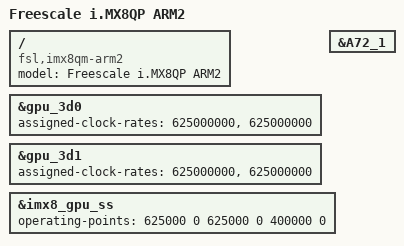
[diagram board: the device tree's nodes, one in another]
/*
 * Copyright (C) 2016 Freescale Semiconductor, Inc.
 * Copyright 2018 NXP
 *
 * This program is free software; you can redistribute it and/or
 * modify it under the terms of the GNU General Public License
 * as published by the Free Software Foundation; either version 2
 * of the License, or (at your option) any later version.
 *
 * This program is distributed in the hope that it will be useful,
 * but WITHOUT ANY WARRANTY; without even the implied warranty of
 * MERCHANTABILITY or FITNESS FOR A PARTICULAR PURPOSE.  See the
 * GNU General Public License for more details.
 */

#include "fsl-imx8qm-lpddr4-arm2.dts"

/ {
        model = "Freescale i.MX8QP ARM2";
        compatible = "fsl,imx8qm-arm2", "fsl,imx8qm";
};

&gpu_3d0 {
      assigned-clock-rates = <625000000>, <625000000>;
};

&gpu_3d1 {
      assigned-clock-rates = <625000000>, <625000000>;
};

&A72_1 {
        device_type = "";
};

&imx8_gpu_ss {/*<freq-kHz vol-uV>*/
	operating-points = <
/*nominal*/	625000	0
		625000	0
/*underdrive*/	400000	0  /*core/shader clock share the same frequency on underdrive mode*/
	>;
};
